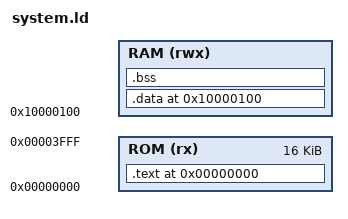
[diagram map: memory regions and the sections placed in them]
MEMORY {
    ROM (rx)  : ORIGIN = 0x00000000, LENGTH = 16K
    RAM (rwx) : ORIGIN = 0x10000100, LENGTH = 4K - 0x100 #First 256 bytes of RAM reserved for USB
}

SECTIONS {
  __stacktop = ORIGIN(RAM) + LENGTH(RAM);

  . = ORIGIN(ROM);
  .text :
  {
    start*(.text)
    *(.text)
    *(.text.*)
    *(.rodata)
    *(.rodata.*)
  } > ROM

  . = ORIGIN(RAM);
  .data :
  {
    *(.data)
  } > RAM
  .bss :
  {
    *(.data)
  } > RAM
}
